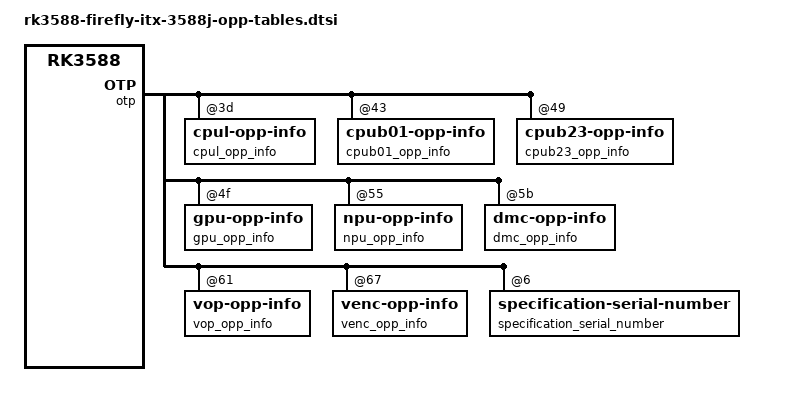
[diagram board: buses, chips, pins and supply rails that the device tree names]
&otp {
	cpul_opp_info: cpul-opp-info@3d {
		reg = <0x3d 0x6>;
	};

	cpub01_opp_info: cpub01-opp-info@43 {
		reg = <0x43 0x6>;
	};

	cpub23_opp_info: cpub23-opp-info@49 {
		reg = <0x49 0x6>;
	};

	gpu_opp_info: gpu-opp-info@4f {
		reg = <0x4f 0x6>;
	};

	npu_opp_info: npu-opp-info@55 {
		reg = <0x55 0x6>;
	};

	dmc_opp_info: dmc-opp-info@5b {
		reg = <0x5b 0x6>;
	};

	vop_opp_info: vop-opp-info@61 {
		reg = <0x61 0x6>;
	};

	venc_opp_info: venc-opp-info@67 {
		reg = <0x67 0x6>;
	};

	specification_serial_number: specification-serial-number@6 {
		reg = <0x06 0x1>;
		bits = <0 5>;
	};
};

/ {
	cluster0_opp_table: opp-table-cluster0 {
		compatible = "operating-points-v2";
		opp-shared;

		/* RK3588 cluster0 OPPs */
		opp-408000000 {
			opp-supported-hw = <0xf9 0xffff>;
			opp-hz = /bits/ 64 <408000000>;
			opp-microvolt = <675000 675000 950000>,
							<675000 675000 950000>;
			clock-latency-ns = <40000>;
		};

		opp-600000000 {
			opp-supported-hw = <0xf9 0xffff>;
			opp-hz = /bits/ 64 <600000000>;
			opp-microvolt = <675000 675000 950000>,
							<675000 675000 950000>;
			clock-latency-ns = <40000>;
		};

		opp-816000000 {
			opp-supported-hw = <0xf9 0xffff>;
			opp-hz = /bits/ 64 <816000000>;
			opp-microvolt = <675000 675000 950000>,
							<675000 675000 950000>;
			clock-latency-ns = <40000>;
		};

		opp-1008000000 {
			opp-supported-hw = <0xf9 0xffff>;
			opp-hz = /bits/ 64 <1008000000>;
			opp-microvolt = <675000 675000 950000>,
							<675000 675000 950000>;
			clock-latency-ns = <40000>;
		};

		opp-1200000000 {
			opp-supported-hw = <0xf9 0xffff>;
			opp-hz = /bits/ 64 <1200000000>;
			opp-microvolt = <712500 712500 950000>,
							<712500 712500 950000>;
			opp-microvolt-L1 = <700000 700000 950000>,
							   <700000 700000 950000>;
			opp-microvolt-L2 = <700000 700000 950000>,
							   <700000 700000 950000>;
			opp-microvolt-L3 = <687500 687500 950000>,
							   <687500 687500 950000>;
			opp-microvolt-L4 = <675000 675000 950000>,
							   <675000 675000 950000>;
			opp-microvolt-L5 = <675000 675000 950000>,
							   <675000 675000 950000>;
			opp-microvolt-L6 = <675000 675000 950000>,
							   <675000 675000 950000>;
			clock-latency-ns = <40000>;
		};

		opp-1416000000 {
			opp-supported-hw = <0xf9 0xffff>;
			opp-hz = /bits/ 64 <1416000000>;
			opp-microvolt = <762500 762500 950000>,
							<762500 762500 950000>;
			opp-microvolt-L1 = <750000 750000 950000>,
							   <750000 750000 950000>;
			opp-microvolt-L2 = <737500 737500 950000>,
							   <737500 737500 950000>;
			opp-microvolt-L3 = <725000 725000 950000>,
							   <725000 725000 950000>;
			opp-microvolt-L4 = <725000 725000 950000>,
							   <725000 725000 950000>;
			opp-microvolt-L5 = <712500 712500 950000>,
							   <712500 712500 950000>;
			opp-microvolt-L6 = <712500 712500 950000>,
							   <712500 712500 950000>;
			clock-latency-ns = <40000>;
			opp-suspend;
		};

		opp-1608000000 {
			opp-supported-hw = <0xf9 0xffff>;
			opp-hz = /bits/ 64 <1608000000>;
			opp-microvolt = <850000 850000 950000>,
							<850000 850000 950000>;
			opp-microvolt-L1 = <837500 837500 950000>,
							   <837500 837500 950000>;
			opp-microvolt-L2 = <825000 825000 950000>,
							   <825000 825000 950000>;
			opp-microvolt-L3 = <812500 812500 950000>,
							   <812500 812500 950000>;
			opp-microvolt-L4 = <800000 800000 950000>,
							   <800000 800000 950000>;
			opp-microvolt-L5 = <800000 800000 950000>,
							   <800000 800000 950000>;
			opp-microvolt-L6 = <787500 787500 950000>,
							   <787500 787500 950000>;
			clock-latency-ns = <40000>;
		};

		opp-1800000000 {
			opp-supported-hw = <0xf9 0xffff>;
			opp-hz = /bits/ 64 <1800000000>;
			opp-microvolt = <950000 950000 950000>,
							<950000 950000 950000>;
			opp-microvolt-L1 = <937500 937500 950000>,
							   <937500 937500 950000>;
			opp-microvolt-L2 = <925000 925000 950000>,
							   <925000 925000 950000>;
			opp-microvolt-L3 = <912500 912500 950000>,
							   <912500 912500 950000>;
			opp-microvolt-L4 = <900000 900000 950000>,
							   <900000 900000 950000>;
			opp-microvolt-L5 = <887500 887500 950000>,
							   <887500 887500 950000>;
			opp-microvolt-L6 = <875000 875000 950000>,
							   <875000 875000 950000>;
			clock-latency-ns = <40000>;
		};

		/* RK3588J/M cluster0 OPPs */
		opp-0408000000 {
			opp-supported-hw = <0x06 0xffff>;
			opp-hz = /bits/ 64 <408000000>;
			opp-microvolt = <750000 750000 950000>,
							<750000 750000 950000>;
			clock-latency-ns = <40000>;
		};

		opp-0600000000 {
			opp-supported-hw = <0x06 0xffff>;
			opp-hz = /bits/ 64 <600000000>;
			opp-microvolt = <750000 750000 950000>,
							<750000 750000 950000>;
			clock-latency-ns = <40000>;
		};

		opp-0816000000 {
			opp-supported-hw = <0x06 0xffff>;
			opp-hz = /bits/ 64 <816000000>;
			opp-microvolt = <750000 750000 950000>,
							<750000 750000 950000>;
			clock-latency-ns = <40000>;
		};

		opp-01008000000 {
			opp-supported-hw = <0x06 0xffff>;
			opp-hz = /bits/ 64 <1008000000>;
			opp-microvolt = <750000 750000 950000>,
							<750000 750000 950000>;
			clock-latency-ns = <40000>;
		};

		opp-01200000000 {
			opp-supported-hw = <0x06 0xffff>;
			opp-hz = /bits/ 64 <1200000000>;
			opp-microvolt = <750000 750000 950000>,
							<750000 750000 950000>;
			clock-latency-ns = <40000>;
		};

		opp-01296000000 {
			opp-supported-hw = <0x04 0xffff>;
			opp-hz = /bits/ 64 <1296000000>;
			opp-microvolt = <750000 750000 950000>,
							<750000 750000 950000>;
			opp-microvolt-L0 = <775000 775000 950000>,
							   <775000 775000 950000>;
			opp-microvolt-L1 = <762500 762500 950000>,
							   <762500 762500 950000>;
			clock-latency-ns = <40000>;
		};

		opp-01416000000 {
			opp-supported-hw = <0x06 0xffff>;
			opp-hz = /bits/ 64 <1416000000>;
			opp-microvolt = <750000 750000 950000>,
							<750000 750000 950000>;
			opp-microvolt-L0 = <787500 787500 950000>,
							   <787500 787500 950000>;
			opp-microvolt-L1 = <775000 775000 950000>,
							   <775000 775000 950000>;
			opp-microvolt-L2 = <762500 762500 950000>,
							   <762500 762500 950000>;
			clock-latency-ns = <40000>;
			opp-suspend;
		};

		opp-01608000000 {
			opp-supported-hw = <0x06 0xffff>;
			opp-hz = /bits/ 64 <1608000000>;
			opp-microvolt = <887500 887500 950000>,
							<887500 887500 950000>;
			opp-microvolt-L1 = <875000 875000 950000>,
							   <875000 875000 950000>;
			opp-microvolt-L2 = <862500 862500 950000>,
							   <862500 862500 950000>;
			opp-microvolt-L3 = <850000 850000 950000>,
							   <850000 850000 950000>;
			opp-microvolt-L4 = <837500 837500 950000>,
							   <837500 837500 950000>;
			opp-microvolt-L5 = <825000 825000 950000>,
							   <825000 825000 950000>;
			opp-microvolt-L6 = <812500 812500 950000>,
							   <812500 812500 950000>;
			clock-latency-ns = <40000>;
		};

		opp-01704000000 {
			opp-supported-hw = <0x06 0xffff>;
			opp-hz = /bits/ 64 <1704000000>;
			opp-microvolt = <937500 937500 950000>,
							<937500 937500 950000>;
			opp-microvolt-L1 = <925000 925000 950000>,
							   <925000 925000 950000>;
			opp-microvolt-L2 = <912500 912500 950000>,
							   <912500 912500 950000>;
			opp-microvolt-L3 = <900000 900000 950000>,
							   <900000 900000 950000>;
			opp-microvolt-L4 = <887500 887500 950000>,
							   <887500 887500 950000>;
			opp-microvolt-L5 = <875000 875000 950000>,
							   <875000 875000 950000>;
			opp-microvolt-L6 = <862500 862500 950000>,
							   <862500 862500 950000>;
			clock-latency-ns = <40000>;
		};
	};

	cluster1_opp_table: opp-table-cluster1 {
		compatible = "operating-points-v2";
		opp-shared;

		/* RK3588 cluster1 OPPs */
		opp-408000000 {
			opp-supported-hw = <0xf9 0xffff>;
			opp-hz = /bits/ 64 <408000000>;
			opp-microvolt = <675000 675000 1000000>,
							<675000 675000 1000000>;
			clock-latency-ns = <40000>;
			opp-suspend;
		};

		opp-600000000 {
			opp-supported-hw = <0xf9 0xffff>;
			opp-hz = /bits/ 64 <600000000>;
			opp-microvolt = <675000 675000 1000000>,
							<675000 675000 1000000>;
			clock-latency-ns = <40000>;
		};

		opp-816000000 {
			opp-supported-hw = <0xf9 0xffff>;
			opp-hz = /bits/ 64 <816000000>;
			opp-microvolt = <675000 675000 1000000>,
							<675000 675000 1000000>;
			clock-latency-ns = <40000>;
		};

		opp-1008000000 {
			opp-supported-hw = <0xf9 0xffff>;
			opp-hz = /bits/ 64 <1008000000>;
			opp-microvolt = <675000 675000 1000000>,
							<675000 675000 1000000>;
			clock-latency-ns = <40000>;
		};

		opp-1200000000 {
			opp-supported-hw = <0xf9 0xffff>;
			opp-hz = /bits/ 64 <1200000000>;
			opp-microvolt = <675000 675000 1000000>,
							<675000 675000 1000000>;
			clock-latency-ns = <40000>;
		};

		opp-1416000000 {
			opp-supported-hw = <0xf9 0xffff>;
			opp-hz = /bits/ 64 <1416000000>;
			opp-microvolt = <725000 725000 1000000>,
							<725000 725000 1000000>;
			opp-microvolt-L2 = <712500 712500 1000000>,
							   <712500 712500 1000000>;
			opp-microvolt-L3 = <700000 700000 1000000>,
							   <700000 700000 1000000>;
			opp-microvolt-L4 = <700000 700000 1000000>,
							   <700000 700000 1000000>;
			opp-microvolt-L5 = <687500 687500 1000000>,
							   <687500 687500 1000000>;
			opp-microvolt-L6 = <675000 675000 1000000>,
							   <675000 675000 1000000>;
			opp-microvolt-L7 = <675000 675000 1000000>,
							   <675000 675000 1000000>;
			clock-latency-ns = <40000>;
		};

		opp-1608000000 {
			opp-supported-hw = <0xf9 0xffff>;
			opp-hz = /bits/ 64 <1608000000>;
			opp-microvolt = <762500 762500 1000000>,
							<762500 762500 1000000>;
			opp-microvolt-L2 = <750000 750000 1000000>,
							   <750000 750000 1000000>;
			opp-microvolt-L3 = <737500 737500 1000000>,
							   <737500 737500 1000000>;
			opp-microvolt-L4 = <725000 725000 1000000>,
							   <725000 725000 1000000>;
			opp-microvolt-L5 = <712500 712500 1000000>,
							   <712500 712500 1000000>;
			opp-microvolt-L6 = <700000 700000 1000000>,
							   <700000 700000 1000000>;
			opp-microvolt-L7 = <700000 700000 1000000>,
							   <700000 700000 1000000>;
			clock-latency-ns = <40000>;
		};

		opp-1800000000 {
			opp-supported-hw = <0xf9 0xffff>;
			opp-hz = /bits/ 64 <1800000000>;
			opp-microvolt = <850000 850000 1000000>,
							<850000 850000 1000000>;
			opp-microvolt-L1 = <837500 837500 1000000>,
							   <837500 837500 1000000>;
			opp-microvolt-L2 = <825000 825000 1000000>,
							   <825000 825000 1000000>;
			opp-microvolt-L3 = <812500 812500 1000000>,
							   <812500 812500 1000000>;
			opp-microvolt-L4 = <800000 800000 1000000>,
							   <800000 800000 1000000>;
			opp-microvolt-L5 = <787500 787500 1000000>,
							   <787500 787500 1000000>;
			opp-microvolt-L6 = <775000 775000 1000000>,
							   <775000 775000 1000000>;
			opp-microvolt-L7 = <762500 762500 1000000>,
							   <762500 762500 1000000>;
			clock-latency-ns = <40000>;
		};

		opp-2016000000 {
			opp-supported-hw = <0xf9 0xffff>;
			opp-hz = /bits/ 64 <2016000000>;
			opp-microvolt = <925000 925000 1000000>,
							<925000 925000 1000000>;
			opp-microvolt-L1 = <912500 912500 1000000>,
							   <912500 912500 1000000>;
			opp-microvolt-L2 = <900000 900000 1000000>,
							   <900000 900000 1000000>;
			opp-microvolt-L3 = <887500 887500 1000000>,
							   <887500 887500 1000000>;
			opp-microvolt-L4 = <875000 875000 1000000>,
							   <875000 875000 1000000>;
			opp-microvolt-L5 = <862500 862500 1000000>,
							   <862500 862500 1000000>;
			opp-microvolt-L6 = <850000 850000 1000000>,
							   <850000 850000 1000000>;
			opp-microvolt-L7 = <837500 837500 1000000>,
							   <837500 837500 1000000>;
			clock-latency-ns = <40000>;
		};

		opp-2208000000 {
			opp-supported-hw = <0xf9 0xffff>;
			opp-hz = /bits/ 64 <2208000000>;
			opp-microvolt = <987500 987500 1000000>,
							<987500 987500 1000000>;
			opp-microvolt-L1 = <975000 975000 1000000>,
							   <975000 975000 1000000>;
			opp-microvolt-L2 = <962500 962500 1000000>,
							   <962500 962500 1000000>;
			opp-microvolt-L3 = <950000 950000 1000000>,
							   <950000 950000 1000000>;
			opp-microvolt-L4 = <962500 962500 1000000>,
							   <962500 962500 1000000>;
			opp-microvolt-L5 = <950000 950000 1000000>,
							   <950000 950000 1000000>;
			opp-microvolt-L6 = <925000 925000 1000000>,
							   <925000 925000 1000000>;
			opp-microvolt-L7 = <912500 912500 1000000>,
							   <912500 912500 1000000>;
			clock-latency-ns = <40000>;
		};

		opp-2256000000 {
			opp-supported-hw = <0xf9 0x13>;
			opp-hz = /bits/ 64 <2256000000>;
			opp-microvolt = <1000000 1000000 1000000>,
							<1000000 1000000 1000000>;
			clock-latency-ns = <40000>;
		};

		opp-2304000000 {
			opp-supported-hw = <0xf9 0x24>;
			opp-hz = /bits/ 64 <2304000000>;
			opp-microvolt = <1000000 1000000 1000000>,
							<1000000 1000000 1000000>;
			clock-latency-ns = <40000>;
		};

		opp-2352000000 {
			opp-supported-hw = <0xf9 0x48>;
			opp-hz = /bits/ 64 <2352000000>;
			opp-microvolt = <1000000 1000000 1000000>,
							<1000000 1000000 1000000>;
			clock-latency-ns = <40000>;
		};

		opp-2400000000 {
			opp-supported-hw = <0xf9 0x80>;
			opp-hz = /bits/ 64 <2400000000>;
			opp-microvolt = <1000000 1000000 1000000>,
							<1000000 1000000 1000000>;
			clock-latency-ns = <40000>;
		};

		/* RK3588J/M cluster1 OPPs */
		opp-0408000000 {
			opp-supported-hw = <0x06 0xffff>;
			opp-hz = /bits/ 64 <408000000>;
			opp-microvolt = <750000 750000 950000>,
							<750000 750000 950000>;
			clock-latency-ns = <40000>;
		};

		opp-0600000000 {
			opp-supported-hw = <0x06 0xffff>;
			opp-hz = /bits/ 64 <600000000>;
			opp-microvolt = <750000 750000 950000>,
							<750000 750000 950000>;
			clock-latency-ns = <40000>;
		};

		opp-0816000000 {
			opp-supported-hw = <0x06 0xffff>;
			opp-hz = /bits/ 64 <816000000>;
			opp-microvolt = <750000 750000 950000>,
							<750000 750000 950000>;
			clock-latency-ns = <40000>;
		};

		opp-01008000000 {
			opp-supported-hw = <0x06 0xffff>;
			opp-hz = /bits/ 64 <1008000000>;
			opp-microvolt = <750000 750000 950000>,
							<750000 750000 950000>;
			clock-latency-ns = <40000>;
		};

		opp-01200000000 {
			opp-supported-hw = <0x06 0xffff>;
			opp-hz = /bits/ 64 <1200000000>;
			opp-microvolt = <750000 750000 950000>,
							<750000 750000 950000>;
			clock-latency-ns = <40000>;
		};

		opp-01416000000 {
			opp-supported-hw = <0x06 0xffff>;
			opp-hz = /bits/ 64 <1416000000>;
			opp-microvolt = <750000 750000 950000>,
							<750000 750000 950000>;
			opp-microvolt-L0 = <762500 762500 950000>,
							   <762500 762500 950000>;
			clock-latency-ns = <40000>;
			opp-suspend;
		};

		opp-01608000000 {
			opp-supported-hw = <0x06 0xffff>;
			opp-hz = /bits/ 64 <1608000000>;
			opp-microvolt = <787500 787500 950000>,
							<787500 787500 950000>;
			opp-microvolt-L2 = <775000 775000 950000>,
							   <775000 775000 950000>;
			opp-microvolt-L3 = <762500 762500 950000>,
							   <762500 762500 950000>;
			opp-microvolt-L4 = <750000 750000 950000>,
							   <750000 750000 950000>;
			opp-microvolt-L5 = <750000 750000 950000>,
							   <750000 750000 950000>;
			opp-microvolt-L6 = <750000 750000 950000>,
							   <750000 750000 950000>;
			opp-microvolt-L7 = <750000 750000 950000>,
							   <750000 750000 950000>;
			clock-latency-ns = <40000>;
		};

		opp-01800000000 {
			opp-supported-hw = <0x06 0xffff>;
			opp-hz = /bits/ 64 <1800000000>;
			opp-microvolt = <875000 875000 950000>,
							<875000 875000 950000>;
			opp-microvolt-L1 = <862500 862500 950000>,
							   <862500 862500 950000>;
			opp-microvolt-L2 = <850000 850000 950000>,
							   <850000 850000 950000>;
			opp-microvolt-L3 = <837500 837500 950000>,
							   <837500 837500 950000>;
			opp-microvolt-L4 = <825000 825000 950000>,
							   <825000 825000 950000>;
			opp-microvolt-L5 = <812500 812500 950000>,
							   <812500 812500 950000>;
			opp-microvolt-L6 = <800000 800000 950000>,
							   <800000 800000 950000>;
			opp-microvolt-L7 = <787500 787500 950000>,
							   <787500 787500 950000>;
			clock-latency-ns = <40000>;
		};

		opp-02016000000 {
			opp-supported-hw = <0x06 0xffff>;
			opp-hz = /bits/ 64 <2016000000>;
			opp-microvolt = <950000 950000 950000>,
							<950000 950000 950000>;
			opp-microvolt-L1 = <950000 950000 950000>,
							   <950000 950000 950000>;
			opp-microvolt-L2 = <937500 937500 950000>,
							   <937500 937500 950000>;
			opp-microvolt-L3 = <925000 925000 950000>,
							   <925000 925000 950000>;
			opp-microvolt-L4 = <912500 912500 950000>,
							   <912500 912500 950000>;
			opp-microvolt-L5 = <900000 900000 950000>,
							   <900000 900000 950000>;
			opp-microvolt-L6 = <887500 887500 950000>,
							   <887500 887500 950000>;
			opp-microvolt-L7 = <875000 875000 950000>,
							   <875000 875000 950000>;
			clock-latency-ns = <40000>;
		};
	};

	cluster2_opp_table: opp-table-cluster2 {
		compatible = "operating-points-v2";
		opp-shared;

		/* RK3588 cluster2 OPPs */
		opp-408000000 {
			opp-supported-hw = <0xf9 0x0ffff>;
			opp-hz = /bits/ 64 <408000000>;
			opp-microvolt = <675000 675000 1000000>,
							<675000 675000 1000000>;
			clock-latency-ns = <40000>;
			opp-suspend;
		};

		opp-600000000 {
			opp-supported-hw = <0xf9 0xffff>;
			opp-hz = /bits/ 64 <600000000>;
			opp-microvolt = <675000 675000 1000000>,
							<675000 675000 1000000>;
			clock-latency-ns = <40000>;
		};

		opp-816000000 {
			opp-supported-hw = <0xf9 0xffff>;
			opp-hz = /bits/ 64 <816000000>;
			opp-microvolt = <675000 675000 1000000>,
							<675000 675000 1000000>;
			clock-latency-ns = <40000>;
		};

		opp-1008000000 {
			opp-supported-hw = <0xf9 0xffff>;
			opp-hz = /bits/ 64 <1008000000>;
			opp-microvolt = <675000 675000 1000000>,
							<675000 675000 1000000>;
			clock-latency-ns = <40000>;
		};

		opp-1200000000 {
			opp-supported-hw = <0xf9 0xffff>;
			opp-hz = /bits/ 64 <1200000000>;
			opp-microvolt = <675000 675000 1000000>,
							<675000 675000 1000000>;
			clock-latency-ns = <40000>;
		};

		opp-1416000000 {
			opp-supported-hw = <0xf9 0xffff>;
			opp-hz = /bits/ 64 <1416000000>;
			opp-microvolt = <725000 725000 1000000>,
							<725000 725000 1000000>;
			opp-microvolt-L2 = <712500 712500 1000000>,
							   <712500 712500 1000000>;
			opp-microvolt-L3 = <700000 700000 1000000>,
							   <700000 700000 1000000>;
			opp-microvolt-L4 = <700000 700000 1000000>,
							   <700000 700000 1000000>;
			opp-microvolt-L5 = <687500 687500 1000000>,
							   <687500 687500 1000000>;
			opp-microvolt-L6 = <675000 675000 1000000>,
							   <675000 675000 1000000>;
			opp-microvolt-L7 = <675000 675000 1000000>,
							   <675000 675000 1000000>;
			clock-latency-ns = <40000>;
		};

		opp-1608000000 {
			opp-supported-hw = <0xf9 0xffff>;
			opp-hz = /bits/ 64 <1608000000>;
			opp-microvolt = <762500 762500 1000000>,
							<762500 762500 1000000>;
			opp-microvolt-L2 = <750000 750000 1000000>,
							   <750000 750000 1000000>;
			opp-microvolt-L3 = <737500 737500 1000000>,
							   <737500 737500 1000000>;
			opp-microvolt-L4 = <725000 725000 1000000>,
							   <725000 725000 1000000>;
			opp-microvolt-L5 = <712500 712500 1000000>,
							   <712500 712500 1000000>;
			opp-microvolt-L6 = <700000 700000 1000000>,
							   <700000 700000 1000000>;
			opp-microvolt-L7 = <700000 700000 1000000>,
							   <700000 700000 1000000>;
			clock-latency-ns = <40000>;
		};

		opp-1800000000 {
			opp-supported-hw = <0xf9 0xffff>;
			opp-hz = /bits/ 64 <1800000000>;
			opp-microvolt = <850000 850000 1000000>,
							<850000 850000 1000000>;
			opp-microvolt-L1 = <837500 837500 1000000>,
							   <837500 837500 1000000>;
			opp-microvolt-L2 = <825000 825000 1000000>,
							   <825000 825000 1000000>;
			opp-microvolt-L3 = <812500 812500 1000000>,
							   <812500 812500 1000000>;
			opp-microvolt-L4 = <800000 800000 1000000>,
							   <800000 800000 1000000>;
			opp-microvolt-L5 = <787500 787500 1000000>,
							   <787500 787500 1000000>;
			opp-microvolt-L6 = <775000 775000 1000000>,
							   <775000 775000 1000000>;
			opp-microvolt-L7 = <762500 762500 1000000>,
							   <762500 762500 1000000>;
			clock-latency-ns = <40000>;
		};

		opp-2016000000 {
			opp-supported-hw = <0xf9 0xffff>;
			opp-hz = /bits/ 64 <2016000000>;
			opp-microvolt = <925000 925000 1000000>,
							<925000 925000 1000000>;
			opp-microvolt-L1 = <912500 912500 1000000>,
							   <912500 912500 1000000>;
			opp-microvolt-L2 = <900000 900000 1000000>,
							   <900000 900000 1000000>;
			opp-microvolt-L3 = <887500 887500 1000000>,
							   <887500 887500 1000000>;
			opp-microvolt-L4 = <875000 875000 1000000>,
							   <875000 875000 1000000>;
			opp-microvolt-L5 = <862500 862500 1000000>,
							   <862500 862500 1000000>;
			opp-microvolt-L6 = <850000 850000 1000000>,
							   <850000 850000 1000000>;
			opp-microvolt-L7 = <837500 837500 1000000>,
							   <837500 837500 1000000>;
			clock-latency-ns = <40000>;
		};

		opp-2208000000 {
			opp-supported-hw = <0xf9 0xffff>;
			opp-hz = /bits/ 64 <2208000000>;
			opp-microvolt = <987500 987500 1000000>,
							<987500 987500 1000000>;
			opp-microvolt-L3 = <975000 975000 1000000>,
							   <975000 975000 1000000>;
			opp-microvolt-L4 = <962500 962500 1000000>,
							   <962500 962500 1000000>;
			opp-microvolt-L5 = <950000 950000 1000000>,
							   <950000 950000 1000000>;
			opp-microvolt-L6 = <925000 925000 1000000>,
							   <925000 925000 1000000>;
			opp-microvolt-L7 = <912500 912500 1000000>,
							   <912500 912500 1000000>;
			clock-latency-ns = <40000>;
		};

		opp-2256000000 {
			opp-supported-hw = <0xf9 0x13>;
			opp-hz = /bits/ 64 <2256000000>;
			opp-microvolt = <1000000 1000000 1000000>,
							<1000000 1000000 1000000>;
			clock-latency-ns = <40000>;
		};

		opp-2304000000 {
			opp-supported-hw = <0xf9 0x24>;
			opp-hz = /bits/ 64 <2304000000>;
			opp-microvolt = <1000000 1000000 1000000>,
							<1000000 1000000 1000000>;
			clock-latency-ns = <40000>;
		};

		opp-2352000000 {
			opp-supported-hw = <0xf9 0x48>;
			opp-hz = /bits/ 64 <2352000000>;
			opp-microvolt = <1000000 1000000 1000000>,
							<1000000 1000000 1000000>;
			clock-latency-ns = <40000>;
		};

		opp-2400000000 {
			opp-supported-hw = <0xf9 0x80>;
			opp-hz = /bits/ 64 <2400000000>;
			opp-microvolt = <1000000 1000000 1000000>,
							<1000000 1000000 1000000>;
			clock-latency-ns = <40000>;
		};

		/* RK3588J/M cluster2 OPPs */
		opp-0408000000 {
			opp-supported-hw = <0x06 0xffff>;
			opp-hz = /bits/ 64 <408000000>;
			opp-microvolt = <750000 750000 950000>,
							<750000 750000 950000>;
			clock-latency-ns = <40000>;
		};

		opp-0600000000 {
			opp-supported-hw = <0x06 0xffff>;
			opp-hz = /bits/ 64 <600000000>;
			opp-microvolt = <750000 750000 950000>,
							<750000 750000 950000>;
			clock-latency-ns = <40000>;
		};

		opp-0816000000 {
			opp-supported-hw = <0x06 0xffff>;
			opp-hz = /bits/ 64 <816000000>;
			opp-microvolt = <750000 750000 950000>,
							<750000 750000 950000>;
			clock-latency-ns = <40000>;
		};

		opp-01008000000 {
			opp-supported-hw = <0x06 0xffff>;
			opp-hz = /bits/ 64 <1008000000>;
			opp-microvolt = <750000 750000 950000>,
							<750000 750000 950000>;
			clock-latency-ns = <40000>;
		};

		opp-01200000000 {
			opp-supported-hw = <0x06 0xffff>;
			opp-hz = /bits/ 64 <1200000000>;
			opp-microvolt = <750000 750000 950000>,
							<750000 750000 950000>;
			clock-latency-ns = <40000>;
		};

		opp-01416000000 {
			opp-supported-hw = <0x06 0xffff>;
			opp-hz = /bits/ 64 <1416000000>;
			opp-microvolt = <750000 750000 950000>,
							<750000 750000 950000>;
			opp-microvolt-L0 = <762500 762500 950000>,
							   <762500 762500 950000>;
			clock-latency-ns = <40000>;
			opp-suspend;
		};

		opp-01608000000 {
			opp-supported-hw = <0x06 0xffff>;
			opp-hz = /bits/ 64 <1608000000>;
			opp-microvolt = <787500 787500 950000>,
							<787500 787500 950000>;
			opp-microvolt-L2 = <775000 775000 950000>,
							   <775000 775000 950000>;
			opp-microvolt-L3 = <762500 762500 950000>,
							   <762500 762500 950000>;
			opp-microvolt-L4 = <750000 750000 950000>,
							   <750000 750000 950000>;
			opp-microvolt-L5 = <750000 750000 950000>,
							   <750000 750000 950000>;
			opp-microvolt-L6 = <750000 750000 950000>,
							   <750000 750000 950000>;
			opp-microvolt-L7 = <750000 750000 950000>,
							   <750000 750000 950000>;
			clock-latency-ns = <40000>;
		};

		opp-01800000000 {
			opp-supported-hw = <0x06 0xffff>;
			opp-hz = /bits/ 64 <1800000000>;
			opp-microvolt = <875000 875000 950000>,
							<875000 875000 950000>;
			opp-microvolt-L1 = <862500 862500 950000>,
							   <862500 862500 950000>;
			opp-microvolt-L2 = <850000 850000 950000>,
							   <850000 850000 950000>;
			opp-microvolt-L3 = <837500 837500 950000>,
							   <837500 837500 950000>;
			opp-microvolt-L4 = <825000 825000 950000>,
							   <825000 825000 950000>;
			opp-microvolt-L5 = <812500 812500 950000>,
							   <812500 812500 950000>;
			opp-microvolt-L6 = <800000 800000 950000>,
							   <800000 800000 950000>;
			opp-microvolt-L7 = <787500 787500 950000>,
							   <787500 787500 950000>;
			clock-latency-ns = <40000>;
		};

		opp-02016000000 {
			opp-supported-hw = <0x06 0xffff>;
			opp-hz = /bits/ 64 <2016000000>;
			opp-microvolt = <950000 950000 950000>,
							<950000 950000 950000>;
			opp-microvolt-L1 = <950000 950000 950000>,
							   <950000 950000 950000>;
			opp-microvolt-L2 = <937500 937500 950000>,
							   <937500 937500 950000>;
			opp-microvolt-L3 = <925000 925000 950000>,
							   <925000 925000 950000>;
			opp-microvolt-L4 = <912500 912500 950000>,
							   <912500 912500 950000>;
			opp-microvolt-L5 = <900000 900000 950000>,
							   <900000 900000 950000>;
			opp-microvolt-L6 = <887500 887500 950000>,
							   <887500 887500 950000>;
			opp-microvolt-L7 = <875000 875000 950000>,
							   <875000 875000 950000>;
			clock-latency-ns = <40000>;
		};
	};

	dmc_opp_table: opp-table-dmc {
		compatible = "operating-points-v2";

		/* RK3588 dmc OPPs */
		opp-528000000 {
			opp-supported-hw = <0xf9 0xffff>;
			opp-hz = /bits/ 64 <528000000>;
			opp-microvolt = <675000 675000 875000>,
							<725000 725000 750000>;
			opp-microvolt-L1 = <675000 675000 875000>,
							   <700000 700000 750000>;
			opp-microvolt-L2 = <675000 675000 875000>,
							   <687500 687500 750000>;
			opp-microvolt-L3 = <675000 675000 875000>,
							   <675000 675000 750000>;
		};

		opp-1068000000 {
			opp-supported-hw = <0xf9 0xffff>;
			opp-hz = /bits/ 64 <1068000000>;
			opp-microvolt = <725000 725000 875000>,
							<737500 737500 750000>;
			opp-microvolt-L1 = <700000 700000 875000>,
							   <712500 712500 750000>;
			opp-microvolt-L2 = <675000 675000 875000>,
							   <700000 700000 750000>;
			opp-microvolt-L3 = <675000 675000 875000>,
							   <687500 687500 750000>;
		};

		opp-1560000000 {
			opp-supported-hw = <0xf9 0xffff>;
			opp-hz = /bits/ 64 <1560000000>;
			opp-microvolt = <800000 800000 875000>,
							<750000 750000 750000>;
			opp-microvolt-L1 = <775000 775000 875000>,
							   <725000 725000 750000>;
			opp-microvolt-L2 = <750000 750000 875000>,
							   <712500 712500 750000>;
			opp-microvolt-L3 = <725000 725000 875000>,
							   <700000 700000 750000>;
		};

		opp-2750000000 {
			opp-supported-hw = <0xf9 0xffff>;
			opp-hz = /bits/ 64 <2750000000>;
			opp-microvolt = <875000 875000 875000>,
							<750000 750000 750000>;
			opp-microvolt-L1 = <850000 850000 875000>,
							   <750000 750000 750000>;
			opp-microvolt-L2 = <837500 837500 875000>,
							   <725000 725000 750000>;
			opp-microvolt-L3 = <825000 820000 875000>,
							   <700000 700000 750000>;
		};

		/* RK3588J/M dmc OPPs */
		opp-0528000000 {
			opp-supported-hw = <0x06 0xffff>;
			opp-hz = /bits/ 64 <528000000>;
			opp-microvolt = <750000 750000 875000>,
							<750000 750000 750000>;
		};

		opp-01068000000 {
			opp-supported-hw = <0x06 0xffff>;
			opp-hz = /bits/ 64 <1068000000>;
			opp-microvolt = <750000 750000 875000>,
							<750000 750000 750000>;
		};

		opp-01560000000 {
			opp-supported-hw = <0x06 0xffff>;
			opp-hz = /bits/ 64 <1560000000>;
			opp-microvolt = <800000 800000 875000>,
							<750000 750000 750000>;
			opp-microvolt-L1 = <775000 775000 875000>,
							   <750000 750000 750000>;
			opp-microvolt-L2 = <750000 750000 875000>,
							   <750000 750000 750000>;
			opp-microvolt-L3 = <750000 750000 875000>,
							   <750000 750000 750000>;
		};

		opp-02750000000 {
			opp-supported-hw = <0x06 0xffff>;
			opp-hz = /bits/ 64 <2750000000>;
			opp-microvolt = <875000 875000 875000>,
							<750000 750000 750000>;
			opp-microvolt-L1 = <850000 850000 875000>,
							   <750000 750000 750000>;
			opp-microvolt-L2 = <837500 837500 875000>,
							   <750000 750000 750000>;
			opp-microvolt-L3 = <825000 820000 875000>,
							   <750000 750000 750000>;
		};
	};

	npu_opp_table: opp-table-npu {
		compatible = "operating-points-v2";

		/* RK3588 npu OPPs */
		opp-300000000 {
			opp-supported-hw = <0xf9 0xffff>;
			opp-hz = /bits/ 64 <300000000>;
			opp-microvolt = <700000 700000 850000>,
							<700000 700000 850000>;
			opp-microvolt-L1 = <687500 687500 850000>,
							   <687500 687500 850000>;
			opp-microvolt-L2 = <675000 675000 850000>,
							   <675000 675000 850000>;
			opp-microvolt-L3 = <675000 675000 850000>,
							   <675000 675000 850000>;
			opp-microvolt-L4 = <675000 675000 850000>,
							   <675000 675000 850000>;
			opp-microvolt-L5 = <675000 675000 850000>,
							   <675000 675000 850000>;
		};

		opp-400000000 {
			opp-supported-hw = <0xf9 0xffff>;
			opp-hz = /bits/ 64 <400000000>;
			opp-microvolt = <700000 700000 850000>,
							<700000 700000 850000>;
			opp-microvolt-L1 = <687500 687500 850000>,
							   <687500 687500 850000>;
			opp-microvolt-L2 = <675000 675000 850000>,
							   <675000 675000 850000>;
			opp-microvolt-L3 = <675000 675000 850000>,
							   <675000 675000 850000>;
			opp-microvolt-L4 = <675000 675000 850000>,
							   <675000 675000 850000>;
			opp-microvolt-L5 = <675000 675000 850000>,
							   <675000 675000 850000>;
		};

		opp-500000000 {
			opp-supported-hw = <0xf9 0xffff>;
			opp-hz = /bits/ 64 <500000000>;
			opp-microvolt = <700000 700000 850000>,
							<700000 700000 850000>;
			opp-microvolt-L1 = <687500 687500 850000>,
							   <687500 687500 850000>;
			opp-microvolt-L2 = <675000 675000 850000>,
							   <675000 675000 850000>;
			opp-microvolt-L3 = <675000 675000 850000>,
							   <675000 675000 850000>;
			opp-microvolt-L4 = <675000 675000 850000>,
							   <675000 675000 850000>;
			opp-microvolt-L5 = <675000 675000 850000>,
							   <675000 675000 850000>;
		};

		opp-600000000 {
			opp-supported-hw = <0xf9 0xffff>;
			opp-hz = /bits/ 64 <600000000>;
			opp-microvolt = <700000 700000 850000>,
							<700000 700000 850000>;
			opp-microvolt-L1 = <687500 687500 850000>,
							   <687500 687500 850000>;
			opp-microvolt-L2 = <675000 675000 850000>,
							   <675000 675000 850000>;
			opp-microvolt-L3 = <675000 675000 850000>,
							   <675000 675000 850000>;
			opp-microvolt-L4 = <675000 675000 850000>,
							   <675000 675000 850000>;
			opp-microvolt-L5 = <675000 675000 850000>,
							   <675000 675000 850000>;
		};

		opp-700000000 {
			opp-supported-hw = <0xf9 0xffff>;
			opp-hz = /bits/ 64 <700000000>;
			opp-microvolt = <700000 700000 850000>,
							<700000 700000 850000>;
			opp-microvolt-L3 = <687500 687500 850000>,
							   <687500 687500 850000>;
			opp-microvolt-L4 = <675000 675000 850000>,
							   <675000 675000 850000>;
			opp-microvolt-L5 = <675000 675000 850000>,
							   <675000 675000 850000>;
		};

		opp-800000000 {
			opp-supported-hw = <0xf9 0xffff>;
			opp-hz = /bits/ 64 <800000000>;
			opp-microvolt = <750000 750000 850000>,
							<750000 750000 850000>;
			opp-microvolt-L2 = <737500 737500 850000>,
							   <737500 737500 850000>;
			opp-microvolt-L3 = <725000 725000 850000>,
							   <725000 725000 850000>;
			opp-microvolt-L4 = <712500 712500 850000>,
							   <712500 712500 850000>;
			opp-microvolt-L5 = <700000 700000 850000>,
							   <700000 700000 850000>;
		};

		opp-900000000 {
			opp-supported-hw = <0xf9 0xffff>;
			opp-hz = /bits/ 64 <900000000>;
			opp-microvolt = <800000 800000 850000>,
							<800000 800000 850000>;
			opp-microvolt-L1 = <787500 787500 850000>,
							   <787500 787500 850000>;
			opp-microvolt-L2 = <775000 775000 850000>,
							   <775000 775000 850000>;
			opp-microvolt-L3 = <762500 762500 850000>,
							   <762500 762500 850000>;
			opp-microvolt-L4 = <750000 750000 850000>,
							   <750000 750000 850000>;
			opp-microvolt-L5 = <737500 737500 850000>,
							   <737500 737500 850000>;
		};

		opp-1000000000 {
			opp-supported-hw = <0xf9 0xffff>;
			opp-hz = /bits/ 64 <1000000000>;
			opp-microvolt = <850000 850000 850000>,
							<850000 850000 850000>;
			opp-microvolt-L1 = <837500 837500 850000>,
							   <837500 837500 850000>;
			opp-microvolt-L2 = <825000 825000 850000>,
							   <825000 825000 850000>;
			opp-microvolt-L3 = <812500 812500 850000>,
							   <812500 812500 850000>;
			opp-microvolt-L4 = <800000 800000 850000>,
							   <800000 800000 850000>;
			opp-microvolt-L5 = <787500 787500 850000>,
							   <787500 787500 850000>;
		};

		/* RK3588J/M npu OPPs */
		opp-0300000000 {
			opp-supported-hw = <0x06 0xffff>;
			opp-hz = /bits/ 64 <300000000>;
			opp-microvolt = <750000 750000 850000>,
							<750000 750000 850000>;
		};

		opp-0400000000 {
			opp-supported-hw = <0x06 0xffff>;
			opp-hz = /bits/ 64 <400000000>;
			opp-microvolt = <750000 750000 850000>,
							<750000 750000 850000>;
		};

		opp-0500000000 {
			opp-supported-hw = <0x06 0xffff>;
			opp-hz = /bits/ 64 <500000000>;
			opp-microvolt = <750000 750000 850000>,
							<750000 750000 850000>;
		};

		opp-0600000000 {
			opp-supported-hw = <0x06 0xffff>;
			opp-hz = /bits/ 64 <600000000>;
			opp-microvolt = <750000 750000 850000>,
							<750000 750000 850000>;
		};

		opp-0700000000 {
			opp-supported-hw = <0x06 0xffff>;
			opp-hz = /bits/ 64 <700000000>;
			opp-microvolt = <750000 750000 850000>,
							<750000 750000 850000>;
		};

		opp-0800000000 {
			opp-supported-hw = <0x06 0xffff>;
			opp-hz = /bits/ 64 <800000000>;
			opp-microvolt = <750000 750000 850000>,
							<750000 750000 850000>;
		};

		opp-0950000000 {
			opp-supported-hw = <0x06 0xffff>;
			opp-hz = /bits/ 64 <950000000>;
			opp-microvolt = <837500 837500 850000>,
							<837500 837500 850000>;
			opp-microvolt-L1 = <825000 825000 850000>,
							   <825000 825000 850000>;
			opp-microvolt-L2 = <812500 812500 850000>,
							   <812500 812500 850000>;
			opp-microvolt-L3 = <800000 800000 850000>,
							   <800000 800000 850000>;
			opp-microvolt-L4 = <787500 787500 850000>,
							   <787500 787500 850000>;
			opp-microvolt-L5 = <775000 775000 850000>,
							   <775000 775000 850000>;
		};
	};

	venc_opp_table: opp-table-venc {
		compatible = "operating-points-v2";

		opp-800000000 {
			opp-hz = /bits/ 64 <800000000>;
			opp-microvolt = <750000 750000 850000>,
							<750000 750000 850000>;
			opp-microvolt-L0 = <800000 800000 850000>,
							   <800000 800000 850000>;
			opp-microvolt-L1 = <775000 775000 850000>,
							   <775000 775000 850000>;
			opp-microvolt-L2 = <750000 750000 850000>,
							   <750000 750000 850000>;
		};
	};

	litcore_grf: syscon@fd594000 {
		compatible = "rockchip,rk3588-litcore-grf", "syscon";
		reg = <0x0 0xfd594000 0x0 0x100>;
	};

	dsu_grf: syscon@fd598000 {
		compatible = "rockchip,rk3588-dsu-grf", "syscon";
		reg = <0x0 0xfd598000 0x0 0x100>;
	};

	npu_grf: syscon@fd5a2000 {
		compatible = "rockchip,rk3588-npu-grf", "syscon";
		reg = <0x0 0xfd5a2000 0x0 0x100>;
	};

	bigcore0_grf: syscon@fd590000 {
		compatible = "rockchip,rk3588-bigcore0-grf", "syscon";
		reg = <0x0 0xfd590000 0x0 0x100>;
	};

	bigcore1_grf: syscon@fd592000 {
		compatible = "rockchip,rk3588-bigcore1-grf", "syscon";
		reg = <0x0 0xfd592000 0x0 0x100>;
	};

};

&gpu_opp_table {

	/* RK3588J/M gpu OPPs */
	opp-0300000000 {
		opp-supported-hw = <0x06 0xffff>;
		opp-hz = /bits/ 64 <300000000>;
		opp-microvolt = <750000 750000 850000>;
	};

	opp-0400000000 {
		opp-supported-hw = <0x06 0xffff>;
		opp-hz = /bits/ 64 <400000000>;
		opp-microvolt = <750000 750000 850000>;
	};

	opp-0500000000 {
		opp-supported-hw = <0x06 0xffff>;
		opp-hz = /bits/ 64 <500000000>;
		opp-microvolt = <750000 750000 850000>;
	};

	opp-0600000000 {
		opp-supported-hw = <0x06 0xffff>;
		opp-hz = /bits/ 64 <600000000>;
		opp-microvolt = <750000 750000 850000>;
	};

	opp-0700000000 {
		opp-supported-hw = <0x06 0xffff>;
		opp-hz = /bits/ 64 <700000000>;
		opp-microvolt = <750000 750000 850000>;
	};

	/* RK3588J gpu OPPs */
	opp-0850000000 {
		opp-supported-hw = <0x04 0xffff>;
		opp-hz = /bits/ 64 <850000000>;
		opp-microvolt = <787500 787500 850000>;
	};

	/* RK3588M gpu OPPs */
	opp-0800000000 {
		opp-supported-hw = <0x02 0xffff>;
		opp-hz = /bits/ 64 <800000000>;
		opp-microvolt = <750000 750000 850000>;
	};

	opp-0900000000 {
		opp-supported-hw = <0x02 0xffff>;
		opp-hz = /bits/ 64 <900000000>;
		opp-microvolt = <800000 800000 850000>;
	};

	opp-01000000000 {
		opp-supported-hw = <0x02 0xffff>;
		opp-hz = /bits/ 64 <1000000000>;
		opp-microvolt = <850000 850000 850000>;
	};
};
